# allwinner_d1_unofficial register map
File version: 0.1
Registers are 32-bit, read-write, reset 0x0 unless marked. A register's access mark holds for its fields unless they carry their own. Offsets are from the block's base; [hi:lo] are bit positions; {n}, {i} and the like mark numbered series.

## SMHC0 — SD/MMC Host Controller
Base 0x04020000
Same registers: SMHC1 0x04021000, SMHC2 0x04022000
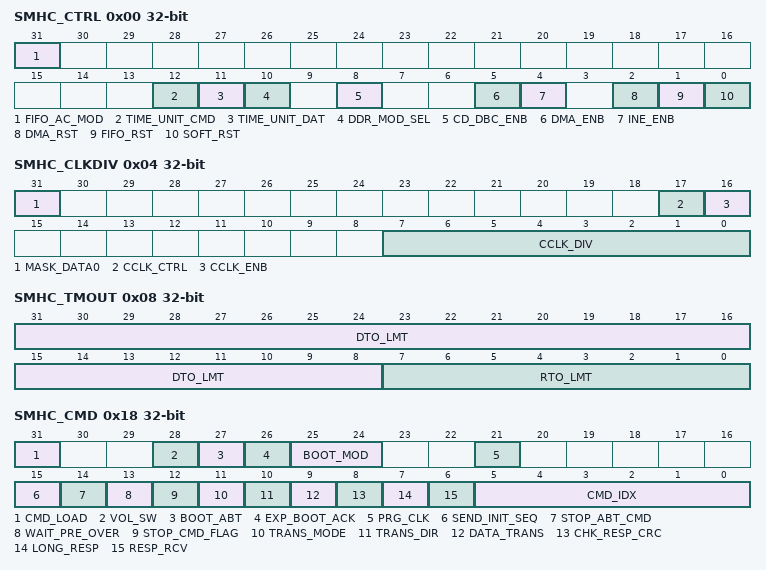
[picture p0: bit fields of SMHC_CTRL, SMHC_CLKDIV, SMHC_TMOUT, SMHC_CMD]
0x00 SMHC_CTRL — Control Register
  [31] FIFO_AC_MOD — FIFO Accesss Mode
    0=DMA (DMA bus); 1=AHB (AHB bus)
  [12] TIME_UNIT_CMD — Time unit for command line
    0=C1 (1 card clock period); 1=C256 (256 card clock period)
  [11] TIME_UNIT_DAT — Time unit for data line
    0=C1 (1 card clock period); 1=C256 (256 card clock period)
  [10] DDR_MOD_SEL — DDR Mode Select
    0=SDR (SDR mode); 1=DDR (DDR mode)
  [8] CD_DBC_ENB — Card Detect (Data[3] status) De-bounce Enable
    0=Disable de-bounce; 1=Enable de-bounce
  [5] DMA_ENB — DMA Global Enable
    0=Disable DMA to transfer data via AHB bus; 1=Enable DMA to transfer data
  [4] INE_ENB — GLobal Interrupt Enable
    0=Disable interrupts; 1=Enable interrupts
  [2] DMA_RST — DMA Reset
  [1] FIFO_RST — FIFO Reset
    0=no_effect; 1=reset
  [0] SOFT_RST — Software Reset
    0=no_effect; 1=reset
0x04 SMHC_CLKDIV — Clock Control Register
  [31] MASK_DATA0
    0=not_mask (Do not mask data0 when update clock); 1=Mask data0 when update clock
  [17] CCLK_CTRL — Card Clock Output Control
    0=on (Card clock is always on); 1=off_idle (Turn off card clock when FSM is in IDLE state)
  [16] CCLK_ENB — Card Clock Enable
    0=off (Card Clock is off); 1=on (Card Clock is on)
  [7:0] CCLK_DIV — Card Clock Divider
0x08 SMHC_TMOUT — Time Out Register
  [31:8] DTO_LMT — Data Iimeout Limit
  [7:0] RTO_LMT — Response Timeout Limit
0x0C SMHC_CTYPE — Bus Width Register
  [1:0] CARD_WID — Card Width
    0=b1 (1-bit width); 1=b4 (4-bit width); 0b1x=b8 (8-bit width)
0x10 SMHC_BLKSIZ — Block Size Register
  [15:0] BLK_SZ — Block SIze
0x14 SMHC_BYTCNT — Byte Count Register
0x18 SMHC_CMD — Command Register
  [31] CMD_LOAD — Start Command
  [28] VOL_SW — Voltage Switch
    0=Normal command; 1=Voltage switch command, set for CMD11 only
  [27] BOOT_ABT — Boot Abort
  [26] EXP_BOOT_ACK — Expect Boot Acknowledge
  [25:24] BOOT_MOD — Boot Mode
    0=Normal command; 1=Mandatory Boot operation; 2=Alternate Boot operation
  [21] PRG_CLK — Change Clock
    0=Normal command; 1=Change Card Clock
  [15] SEND_INIT_SEQ — Send Initialization
    0=Normal command sending; 1=init_cmd (Send initialization sequence before sending this command)
  [14] STOP_ABT_CMD — Stop Abort Command
    0=Normal command sending; 1=stop (Send Stop or Abort command to stop the current data transfer in progress)
  [13] WAIT_PRE_OVER — Wait for Data Transfer Over
    0=at_once (Send command at once, does not care about data transferring); 1=Wait for data transfer completion before sending the current command
  [12] STOP_CMD_FLAG — Send Stop CMD Automatically (CMD12)
    0=no_stop (Do not send stop command at the end of the data transfer); 1=auto_stop (Send stop command automatically at the end of the data transfer)
  [11] TRANS_MODE — Transfer Mode
    0=Block data transfer command; 1=Stream data transfer commmand
  [10] TRANS_DIR — Transfer Direction
    0=Read operation; 1=Write operation
  [9] DATA_TRANS — Data Transfer
    0=Without data transfer; 1=With data transfer
  [8] CHK_RESP_CRC — Check Response CRC
    0=not_check (Do not check response CRC); 1=Check response CRC
  [7] LONG_RESP — Response Type
    0=Short Response (48 bits); 1=Long Response (136 bits)
  [6] RESP_RCV — Response Receive
    0=without (Command without response); 1=with (Command with response)
  [5:0] CMD_IDX — CMD Index
0x1C SMHC_CMDARG — Command Argument Register
{0x20+4i} SMHC_RESP{i} ro (i=0..3) — Response {i} Register
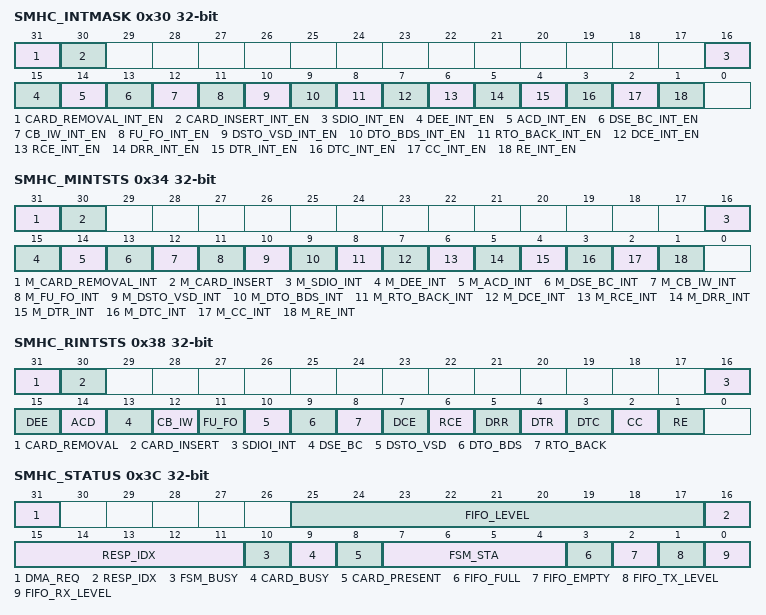
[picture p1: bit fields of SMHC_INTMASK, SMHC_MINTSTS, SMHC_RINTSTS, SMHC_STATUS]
0x30 SMHC_INTMASK — Interrupt Mask Register
  [31] CARD_REMOVAL_INT_EN — Card Removed Interrupt Enable
  [30] CARD_INSERT_INT_EN — Card Inserted Interrupt Enable
  [16] SDIO_INT_EN — SDIO Interrupt Enable
  [15] DEE_INT_EN — Data End-bit Error Interrupt Enable
  [14] ACD_INT_EN — Auto Command Done Interrupt Enable
  [13] DSE_BC_INT_EN — Data Start Error Interrupt Enable
  [12] CB_IW_INT_EN — Command Busy and Illegal Write Interrupt Enable
  [11] FU_FO_INT_EN — FIFO Underrun/Overflow Interrupt Enable
  [10] DSTO_VSD_INT_EN — Data Starvation Timeout/V1.8 Switch Done Interrupt Enable
  [9] DTO_BDS_INT_EN — Data Timeout/Boot Data Start Interrupt Enable
  [8] RTO_BACK_INT_EN — Response Timeout/Boot ACK Received Interrupt Enable
  [7] DCE_INT_EN — Data CRC Error Interrupt Enable
  [6] RCE_INT_EN — Response CRC Error Interrupt Enable
  [5] DRR_INT_EN — Data Receive Request Interrupt Enable
  [4] DTR_INT_EN — Data Transmit Request Interrupt Enable
  [3] DTC_INT_EN — Data Transfer Complete Interrupt Enable
  [2] CC_INT_EN — Command Complete Interrupt Enable
  [1] RE_INT_EN — Response Error Interrupt Enable
0x34 SMHC_MINTSTS ro — Masked Interrupt Status Register
  [31] M_CARD_REMOVAL_INT — Card Removed
  [30] M_CARD_INSERT — Card Inserted
  [16] M_SDIO_INT — SDIO Interrupt
  [15] M_DEE_INT — Data End-bit Error
  [14] M_ACD_INT — Auto Command Done
  [13] M_DSE_BC_INT — Data Start Error/Busy Clear
  [12] M_CB_IW_INT — Command Busy and Illegal Write
  [11] M_FU_FO_INT — FIFO Underrun/Overflow
  [10] M_DSTO_VSD_INT — Data Starvation Timeout/V1.8 Switch Done
  [9] M_DTO_BDS_INT — Data Timeout/Boot Data Start
  [8] M_RTO_BACK_INT — Response Timeout/Boot ACK Received
  [7] M_DCE_INT — Data CRC Error
  [6] M_RCE_INT — Response CRC Error
  [5] M_DRR_INT — Data Receive Request
  [4] M_DTR_INT — Data Transmit Request
  [3] M_DTC_INT — Data Transfer Complete
  [2] M_CC_INT — Command Complete
  [1] M_RE_INT — Response Errors
0x38 SMHC_RINTSTS — Raw Interrupt Status Register
  [31] CARD_REMOVAL — Card Removed
  [30] CARD_INSERT — Card Inserted
  [16] SDIOI_INT — SDIO Interrupt
  [15] DEE — Data End-bit Error
  [14] ACD — Auto Command Done
  [13] DSE_BC — Data Start Error/Busy Clear
  [12] CB_IW — Command Busy and Illegal Write
  [11] FU_FO — FIFO Underrun/Overflow
  [10] DSTO_VSD — Data Starvation Timeout/V1.8 Switch Done
  [9] DTO_BDS — Data Timeout/Boot Data Start
  [8] RTO_BACK — Response Timeout/Boot ACK Received
  [7] DCE — Data CRC Error
  [6] RCE — Response CRC Error
  [5] DRR — Data Receive Request
  [4] DTR — Data Transmit Request
  [3] DTC — Data Transfer Complete
  [2] CC — Command Complete
  [1] RE — Response Error
0x3C SMHC_STATUS ro — Status Register
  [31] DMA_REQ — DMA Request
  [25:17] FIFO_LEVEL
  [16:11] RESP_IDX — Response Index
  [10] FSM_BUSY — Data FSM Busy
  [9] CARD_BUSY — Card Data Busy
    0=not_busy (Card data is not busy); 1=busy (Card data is busy)
  [8] CARD_PRESENT — Data[3] Statuss
    0=not_present (The card is not present); 1=present (The card is present)
  [7:4] FSM_STA — Command FSM States
    0=idle; 1=sis (Send init sequence); 2=txcsb (TX CMD start bit); 3=txctb (TX CMD TX bit); 4=txcia (TX CMD index + argument); 5=txcc (TX CMD CRC7); 6=txceb (TX CMD end bit); 7=rxrsb (RX response start bit); 8=rxrir (RX response IRQ responses); 9=rxrtb (RX response TX bit); 10=rxrci (RX response CMD index); 11=rxrd (RX response data); 12=rxrc (RX response CRC7); 13=rxreb (RX response end bit); 14=cpwn (CMD path wait NCC); 15=Wait; CMD-to-response turn around
  [3] FIFO_FULL — sFIFO Full
    0=not_full (FIFO is not full); 1=full (FIFO is full)
  [2] FIFO_EMPTY
    0=not_sempty (FIFO is not empty); 1=empty (FIFO is empty)
  [1] FIFO_TX_LEVEL — FIFO TX Water Level Flag
    0=not_reach (FIFO does not reach the transmit trigger level); 1=reach (FIFO reaches the transmit trigger level)
  [0] FIFO_RX_LEVEL — FIFO RX Water Level Flag
    0=not_reach (FIFO does not reach the receive trigger level); 1=reach (FIFO reaches the receive trigger level)
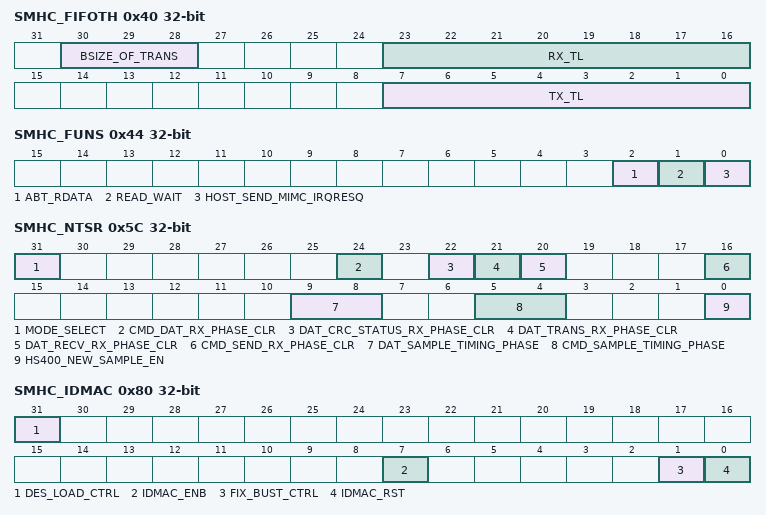
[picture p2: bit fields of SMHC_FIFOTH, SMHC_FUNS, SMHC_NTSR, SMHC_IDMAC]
0x40 SMHC_FIFOTH — FIFO Water Level Register
  [30:28] BSIZE_OF_TRANS — sBurst Size of Multiple Transaction
    0=T1 (1 transfer); 1=T4 (4 transfers); 2=T8 (8 transfers); 3=T16 (16 transfers)
  [23:16] RX_TL — RX Trigger Level
  [7:0] TX_TL — TX Trigger Level
0x44 SMHC_FUNS — FIFO Function Select Register
  [2] ABT_RDATA — Abort Read Data
    0=ignored; 1=abort
  [1] READ_WAIT
    0=Clear SDIO read wait; 1=Assert SDIO read wait
  [0] HOST_SEND_MIMC_IRQRESQ — Host Send MMC IRQ Response
    0=ignored; 1=Send auto IRQ response
0x48 SMHC_TBC0 ro — Transferred Byte Count between Controller and Card
0x4C SMHC_TBC1 ro — Transferred Byte Count between Host Memory and Internal FIFO
0x50 SMHC_DBGC — Current Debug Control Register
0x54 SMHC_CSDC — CRC Status Detect Control Registers
  [3:0] CRC_DET_PARA
    6=HS400; 3=Other
0x58 SMHC_A12A — Auto Command 12 Argument Register
  [15:0] SD_A12A
0x5C SMHC_NTSR — SD New Timing Set Register
  [31] MODE_SELECT
    0=Old mode of Sample/Output Timing; 1=New mode of Sample/Output Timing
  [24] CMD_DAT_RX_PHASE_CLR — Clear the input phase of command lines and data lines during the update clock operation
    0=Disabled; 1=Enabled
  [22] DAT_CRC_STATUS_RX_PHASE_CLR — Clear the input phase of data lines before receiving the CRC status
    0=Disabled; 1=Enabled
  [21] DAT_TRANS_RX_PHASE_CLR — Clear the input phase of data lines before transferring the data
    0=Disabled; 1=Enabled
  [20] DAT_RECV_RX_PHASE_CLR — Clear the input phase of data lines before receiving the data
    0=Disabled; 1=Enabled
  [16] CMD_SEND_RX_PHASE_CLR — Clear command rx phase before sending the command
    0=Disabled; 1=Enabled
  [9:8] DAT_SAMPLE_TIMING_PHASE
    0=O90 (Sample timing phase offset 90); 1=O180 (Sample timing phase offset 180); 2=O270 (Sample timing phase offset 270); 3=O0 (Sample timing phase offset 0 (only for SD2 hs400 mode))
  [5:4] CMD_SAMPLE_TIMING_PHASE
    0=O90 (Sample timing phase offset 90); 1=O180 (Sample timing phase offset 180); 2=O270 (Sample timing phase offset 270); 3=O0 (Ignore)
  [0] HS400_NEW_SAMPLE_EN
    0=Disable hs400 new sample method; 1=Enable hs400 new sample method
0x78 SMHC_HWRST — Hardware Reset Register
  [0] HW_RST
    0=Active mode; 1=Reset
0x80 SMHC_IDMAC — IDMAC Control Register
  [31] DES_LOAD_CTRL wo
  [7] IDMAC_ENB — IDMAC Enable
  [1] FIX_BUST_CTRL — Fixed Burst
  [0] IDMAC_RST — DMA Reset
0x84 SMHC_DLBA — Descriptor List Base Address Register
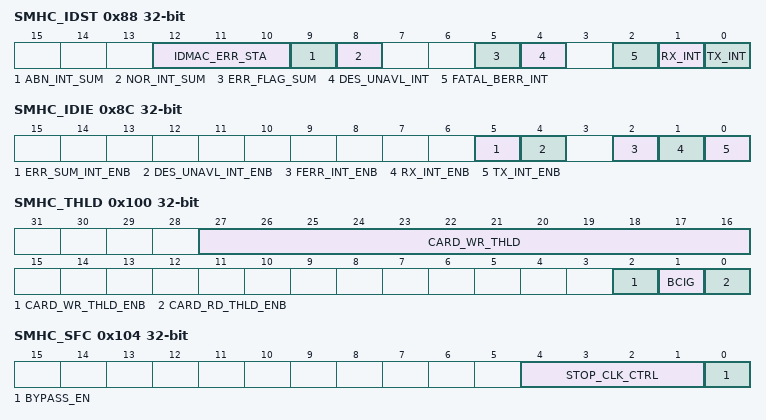
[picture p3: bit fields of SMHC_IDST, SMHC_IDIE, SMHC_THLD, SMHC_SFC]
0x88 SMHC_IDST — IDMAC Status Register
  [12:10] IDMAC_ERR_STA ro — Error Bits
    1=transmission (Host Abort received during the transmission); 2=reception (Host Abort received during the reception)
  [9] ABN_INT_SUM — Abnormal Interrupt Summary
  [8] NOR_INT_SUM — Normal Interrupt Summary
  [5] ERR_FLAG_SUM — Card Error Summary
  [4] DES_UNAVL_INT — Descriptor Unavailable Interrupt
  [2] FATAL_BERR_INT — Fatal Bus Error Interrupt
  [1] RX_INT — Receive Interrupt
  [0] TX_INT — Transmit Interrupt
0x8C SMHC_IDIE — IDMAC Interrupt Enable Register
  [5] ERR_SUM_INT_ENB — Card Error Summary Interrupt Enable
  [4] DES_UNAVL_INT_ENB — Descriptor Unavailable Interrupt
  [2] FERR_INT_ENB — Fatal Bus Error Enable
  [1] RX_INT_ENB — Receive Interrupt Enables
  [0] TX_INT_ENB — Transmit Interrupt Enable
0x100 SMHC_THLD — Card Threshold Control Register
  [27:16] CARD_WR_THLD — Card Read/Write Threshold Size
  [2] CARD_WR_THLD_ENB — Card Read/Write Threshold Enable
    0=disabled (Card write threshold disabled); 1=enabled (Card write threshold enabled)
  [1] BCIG — Busy Clear Interrupt Generation
    0=disabled (Busy clear interrupt disabled); 1=enabled (Busy clear interrupt enabled)
  [0] CARD_RD_THLD_ENB — Card Read Threshold Enable
    0=disabled (Card read threshold disabled); 1=enabled (Card read threshold enabled)
0x104 SMHC_SFC — Sample FIFO Control Register
  [4:1] STOP_CLK_CTRL — Stop Clock Control
  [0] BYPASS_EN — Bypass enable
0x108 SMHC_A23A — Auto Command 23 Argument Register
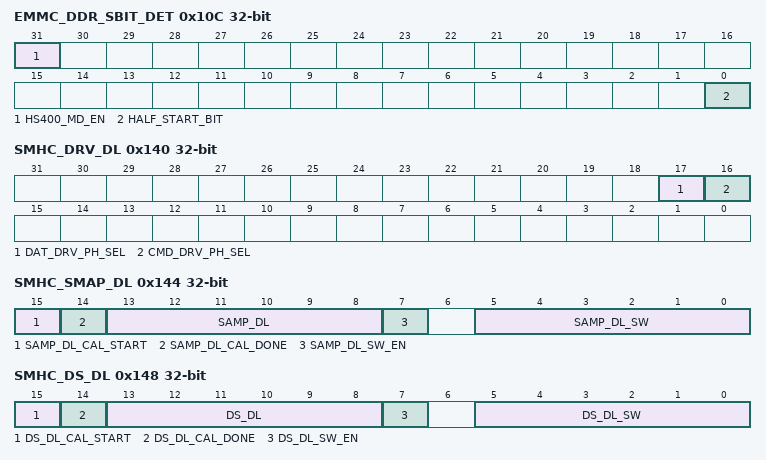
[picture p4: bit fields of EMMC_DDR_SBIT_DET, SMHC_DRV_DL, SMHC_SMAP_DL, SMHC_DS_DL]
0x10C EMMC_DDR_SBIT_DET — eMMC4.5 DDR Start Bit Detection Control Register
  [31] HS400_MD_EN — HS400 Mode Enable
    0=disabled; 1=enabled
  [0] HALF_START_BIT — Control for start bit detection mechanism inside mstorage based on duration of start bit
    0=Full cycle; 1=Less than one full cycle
0x138 SMHC_EXT_CMD — Extended Command Register
  [0] AUTO_CMD23_EN — Send CMD23 Automatically
0x13C SMHC_EXT_RESP ro — Extended Response Register
0x140 SMHC_DRV_DL — Drive Delay Control Register
  [17] DAT_DRV_PH_SEL — Data Drive Phase Select
  [16] CMD_DRV_PH_SEL — Command Drive Phase Select
0x144 SMHC_SMAP_DL — Sample Delay Control Register
  [15] SAMP_DL_CAL_START — Sample Delay Calibration Start
  [14] SAMP_DL_CAL_DONE ro — Sample Delay Calibration Done
  [13:8] SAMP_DL ro — Sample Delay
  [7] SAMP_DL_SW_EN — Sample Delay Software Enable
  [5:0] SAMP_DL_SW — Sample Delay Software
0x148 SMHC_DS_DL — Data Strobe Delay Control Register
  [15] DS_DL_CAL_START — Data Strobe Delay Calibration Start
  [14] DS_DL_CAL_DONE ro — Data Strobe Delay Calibration Done
  [13:8] DS_DL ro — Data Strobe Delay
  [7] DS_DL_SW_EN — Sample Delay Software Enable
  [5:0] DS_DL_SW — Data Storbe Delay Software
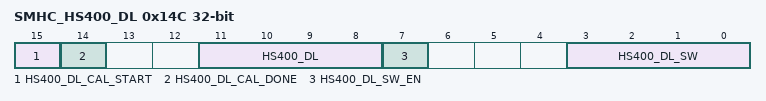
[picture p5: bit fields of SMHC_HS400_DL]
0x14C SMHC_HS400_DL — HS400 Delay Control Register
  [15] HS400_DL_CAL_START — HS400 Delay Calibration Start
  [14] HS400_DL_CAL_DONE ro — HS400 Delay Calibration Done
  [11:8] HS400_DL ro — HS400 Delay
  [7] HS400_DL_SW_EN — Sample Delay Software Enable
  [3:0] HS400_DL_SW — HS400 Delay Software
0x200 SMHC_FIFO — Read/Write FIFO
